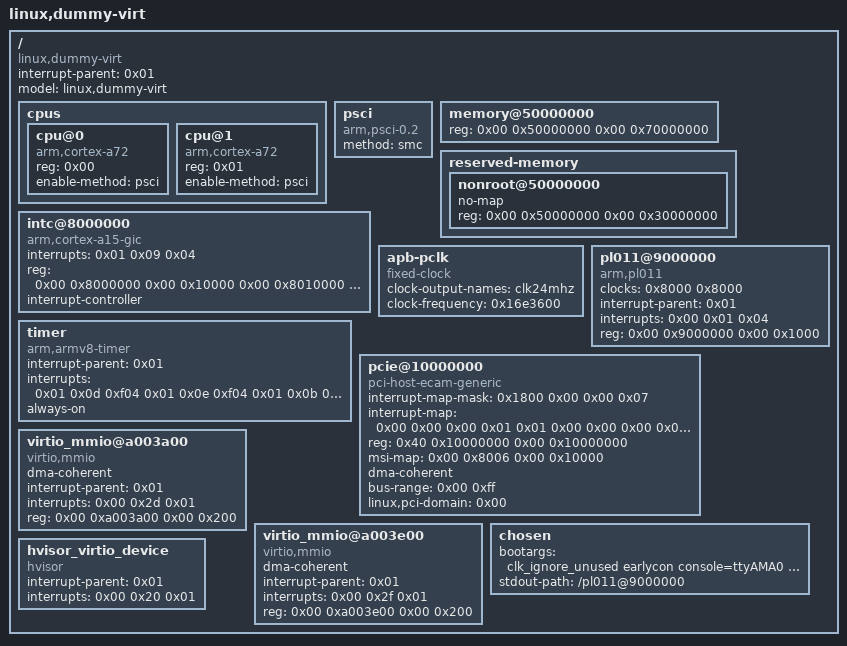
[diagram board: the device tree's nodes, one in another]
/dts-v1/;

/ {
	#size-cells = <0x02>;
	#address-cells = <0x02>;
	interrupt-parent = <0x01>;
	model = "linux,dummy-virt";
	compatible = "linux,dummy-virt";

	cpus {
		#size-cells = <0x00>;
		#address-cells = <0x01>;

		cpu@0 {
			phandle = <0x8010>;
			reg = <0x00>;
			enable-method = "psci";
			compatible = "arm,cortex-a72";
			device_type = "cpu";
		};

		cpu@1 {
			phandle = <0x800f>;
			reg = <0x01>;
			enable-method = "psci";
			compatible = "arm,cortex-a72";
			device_type = "cpu";
		};
	};

	psci {
		compatible = "arm,psci-0.2";
		method = "smc";
	};

	memory@50000000 {
		device_type = "memory";
		reg = <0x00 0x50000000 0x00 0x70000000>;
	};

	reserved-memory {
		#address-cells = <0x02>;
		#size-cells = <0x02>;
		ranges;

		nonroot@50000000 {
			no-map;
			reg = <0x00 0x50000000 0x00 0x30000000>;
		};
	};

	intc@8000000 {
		phandle = <0x01>;
		interrupts = <0x01 0x09 0x04>;
		reg = <0x00 0x8000000 0x00 0x10000 0x00 0x8010000 0x00 0x10000 0x00 0x8030000 0x00 0x10000 0x00 0x8040000 0x00 0x10000>;
		compatible = "arm,cortex-a15-gic";
		ranges;
		#size-cells = <0x02>;
		#address-cells = <0x02>;
		interrupt-controller;
		#interrupt-cells = <0x03>;
	};

	apb-pclk {
		phandle = <0x8000>;
		clock-output-names = "clk24mhz";
		clock-frequency = <0x16e3600>;
		#clock-cells = <0x00>;
		compatible = "fixed-clock";
	};

	pl011@9000000 {
		clock-names = "uartclk\0apb_pclk";
		clocks = <0x8000 0x8000>;
		interrupt-parent = <0x01>;
		interrupts = <0x00 0x01 0x04>;
		reg = <0x00 0x9000000 0x00 0x1000>;
		compatible = "arm,pl011\0arm,primecell";
	};

	timer {
		interrupt-parent = <0x01>;
		interrupts = <0x01 0x0d 0xf04 0x01 0x0e 0xf04 0x01 0x0b 0xf04 0x01 0x0a 0xf04>;
		always-on;
		compatible = "arm,armv8-timer\0arm,armv7-timer";
	};

	pcie@10000000 {
		interrupt-map-mask = <0x1800 0x00 0x00 0x07>;
		interrupt-map = <0x00 0x00 0x00 0x01 0x01 0x00 0x00 0x00 0x03 0x04 0x00 0x00 0x00 0x02 0x01 0x00 0x00 0x00 0x04 0x04 0x00 0x00 0x00 0x03 0x01 0x00 0x00 0x00 0x05 0x04 0x00 0x00 0x00 0x04 0x01 0x00 0x00 0x00 0x06 0x04 0x800 0x00 0x00 0x01 0x01 0x00 0x00 0x00 0x04 0x04 0x800 0x00 0x00 0x02 0x01 0x00 0x00 0x00 0x05 0x04 0x800 0x00 0x00 0x03 0x01 0x00 0x00 0x00 0x06 0x04 0x800 0x00 0x00 0x04 0x01 0x00 0x00 0x00 0x03 0x04 0x1000 0x00 0x00 0x01 0x01 0x00 0x00 0x00 0x05 0x04 0x1000 0x00 0x00 0x02 0x01 0x00 0x00 0x00 0x06 0x04 0x1000 0x00 0x00 0x03 0x01 0x00 0x00 0x00 0x03 0x04 0x1000 0x00 0x00 0x04 0x01 0x00 0x00 0x00 0x04 0x04 0x1800 0x00 0x00 0x01 0x01 0x00 0x00 0x00 0x06 0x04 0x1800 0x00 0x00 0x02 0x01 0x00 0x00 0x00 0x03 0x04 0x1800 0x00 0x00 0x03 0x01 0x00 0x00 0x00 0x04 0x04 0x1800 0x00 0x00 0x04 0x01 0x00 0x00 0x00 0x05 0x04>;
		#interrupt-cells = <0x01>;
		ranges = <0x1000000 0x00 0x00 0x00 0x3eff0000 0x00 0x10000 
		0x2000000 0x00 0x10000000 0x00 0x10000000 0x00 0x2eff0000 
		0x3000000 0x80 0x00 0x80 0x00 0x80 0x00>;
		reg = <0x40 0x10000000 0x00 0x10000000>;
		msi-map = <0x00 0x8006 0x00 0x10000>;
		dma-coherent;
		bus-range = <0x00 0xff>;
		linux,pci-domain = <0x00>;
		#size-cells = <0x02>;
		#address-cells = <0x03>;
		device_type = "pci";
		compatible = "pci-host-ecam-generic";
	};

	virtio_mmio@a003a00 {
		dma-coherent;
		interrupt-parent = <0x01>;
		interrupts = <0x00 0x2d 0x01>;
		reg = <0x00 0xa003a00 0x00 0x200>;
		compatible = "virtio,mmio";
	};

	virtio_mmio@a003e00 {
		dma-coherent;
		interrupt-parent = <0x01>;
		interrupts = <0x00 0x2f 0x01>;
		reg = <0x00 0xa003e00 0x00 0x200>;
		compatible = "virtio,mmio";
	};

	chosen {
		bootargs = "clk_ignore_unused earlycon console=ttyAMA0 root=/dev/vda iomem=relaxed rw";
		stdout-path = "/pl011@9000000";
	};

	hvisor_virtio_device {
		compatible = "hvisor";
		interrupt-parent = <0x01>;
		interrupts = <0x00 0x20 0x01>;
	};
};
